# ATSAMRH707F18A device description
Architecture: CORTEX-M7; Family: SAMRH; Series: SAMRH707
Registers are 32-bit, read-write, no defined reset value unless marked. A register's access mark holds for its fields unless they carry their own. Offsets are from the block's base; [hi:lo] are bit positions.

## CHIPID — Chip Identifier
Instances: CHIPID 0x40100000
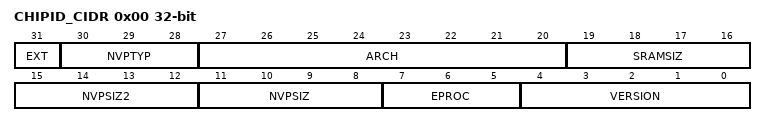
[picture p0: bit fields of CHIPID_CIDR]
0x00 CHIPID_CIDR ro — Chip ID Register
  [31] EXT — Extension Flag
  [30:28] NVPTYP — Nonvolatile Program Memory Type
    0=ROM; 1=ROMLESS (ROMless or on-chip Flash); 2=FLASH (Embedded Flash Memory); 3=ROM_FLASH (ROM and Embedded Flash Memory - NVPSIZ is ROM size - NVPSIZ2 is Flash size); 4=SRAM (SRAM emulating ROM)
  [27:20] ARCH — Architecture Identifier
    23=SAMRH707
  [19:16] SRAMSIZ — Internal SRAM Size
    0=_48K (48 Kbytes); 1=_192K (192 Kbytes); 2=_384K (384 Kbytes); 3=_6K (6 Kbytes); 4=_24K (24 Kbytes); 5=_4K (4 Kbytes); 6=_80K (80 Kbytes); 7=_160K (160 Kbytes); 8=_8K (8 Kbytes); 9=_16K (16 Kbytes); 10=_32K (32 Kbytes); 11=_64K (64 Kbytes); 12=_128K (128 Kbytes); 13=_256K (256 Kbytes); 14=_96K (96 Kbytes); 15=_512K (512 Kbytes)
  [15:12] NVPSIZ2 — Second Nonvolatile Program Memory Size
    0=NONE; 1=_8K (8 Kbytes); 2=_16K (16 Kbytes); 3=_32K (32 Kbytes); 5=_64K (64 Kbytes); 7=_128K (128 Kbytes); 9=_256K (256 Kbytes); 10=_512K (512 Kbytes); 12=_1024K (1024 Kbytes); 14=_2048K (2048 Kbytes)
  [11:8] NVPSIZ — Nonvolatile Program Memory Size
    0=NONE; 1=_8K (8 Kbytes); 2=_16K (16 Kbytes); 3=_32K (32 Kbytes); 5=_64K (64 Kbytes); 7=_128K (128 Kbytes); 8=_160K (160 Kbytes); 9=_256K (256 Kbytes); 10=_512K (512 Kbytes); 12=_1024K (1024 Kbytes); 14=_2048K (2048 Kbytes)
  [7:5] EPROC — Embedded Processor
    0=SAMx7 (Cortex-M7); 1=ARM946ES; 2=ARM7TDMI; 3=CM3 (Cortex-M3); 4=ARM920T; 5=ARM926EJS; 6=CA5 (Cortex-A5); 7=CM4 (Cortex-M4)
  [4:0] VERSION — Version of the Device
0x04 CHIPID_EXID ro — Chip ID Extension Register
  [31:0] EXID — Chip ID Extension
    0=PACKAGE_TYPE_164 (164-lead package); 1=PACKAGE_TYPE_BGA_484 (484-balls BGA package); 2=PACKAGE_TYPE_144 (144-lead package)

## CRCCU — Cyclic Redundancy Check Calculation Unit
Instances: CRCCU 0x40018000
0x00 CRCCU_DSCR — CRCCU Descriptor Base Register
  [31:9] DSCR — Descriptor Base Address
0x08 CRCCU_DMA_EN wo — CRCCU DMA Enable Register
  [0] DMAEN — DMA Enable
0x0C CRCCU_DMA_DIS wo — CRCCU DMA Disable Register
  [0] DMADIS — DMA Disable
0x10 CRCCU_DMA_SR ro — CRCCU DMA Status Register
  [0] DMASR — DMA Status
0x14 CRCCU_DMA_IER wo (atomic set of CRCCU_DMA_IMR) — CRCCU DMA Interrupt Enable Register
  [0] DMAIER — Interrupt Enable
0x18 CRCCU_DMA_IDR wo (atomic clear of CRCCU_DMA_IMR) — CRCCU DMA Interrupt Disable Register
  [0] DMAIDR — Interrupt Disable
0x1C CRCCU_DMA_IMR ro (atomic read) — CRCCU DMA Interrupt Mask Register
  [0] DMAIMR — Interrupt Mask
0x20 CRCCU_DMA_ISR ro (atomic read) — CRCCU DMA Interrupt Status Register
  [0] DMAISR — Interrupt Status
0x34 CRCCU_CR wo — CRCCU Control Register
  [0] RESET — CRC Computation Reset
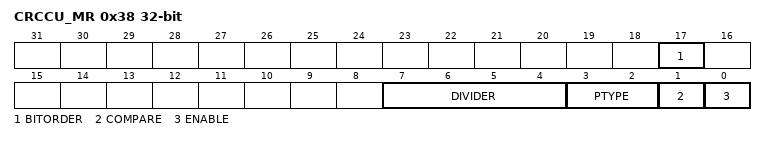
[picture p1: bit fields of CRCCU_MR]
0x38 CRCCU_MR — CRCCU Mode Register
  [17] BITORDER — Precomputation Bit Swap Operation of the CRC
    0=MSBFIRST (CRC computation is performed from the most significant bit to the least significant bit); 1=LSBFIRST (CRC computation is performed from the least significant bit to the most significant bit)
  [7:4] DIVIDER — Request Divider
  [3:2] PTYPE — Primitive Polynomial
    0=CCITT8023 (Polynom 0x04C11DB7); 1=CASTAGNOLI (Polynom 0x1EDC6F41); 2=CCITT16 (Polynom 0x1021)
  [1] COMPARE — CRC Compare
  [0] ENABLE — CRC Enable
0x3C CRCCU_SR ro — CRCCU Status Register
  [31:0] CRC — Cyclic Redundancy Check Value
0x40 CRCCU_IER wo (atomic set of CRCCU_IMR) — CRCCU Interrupt Enable Register
  [0] ERRIER — CRC Error Interrupt Enable
0x44 CRCCU_IDR wo (atomic clear of CRCCU_IMR) — CRCCU Interrupt Disable Register
  [0] ERRIDR — CRC Error Interrupt Disable
0x48 CRCCU_IMR ro (atomic read) — CRCCU Interrupt Mask Register
  [0] ERRIMR — CRC Error Interrupt Mask
0x4C CRCCU_ISR ro (atomic read) — CRCCU Interrupt Status Register
  [0] ERRISR — CRC Error Interrupt Status

## Notices in the file
Copyright (c) 2018 Microchip Technology Inc.
SPDX-License-Identifier: Apache-2.0
Licensed under the Apache License, Version 2.0 (the "License");
you may not use this file except in compliance with the License.
You may obtain a copy of the License at
http://www.apache.org/licenses/LICENSE-2.0
Unless required by applicable law or agreed to in writing, software
distributed under the License is distributed on an "AS IS" BASIS,
WITHOUT WARRANTIES OR CONDITIONS OF ANY KIND, either express or implied.
See the License for the specific language governing permissions and
limitations under the License.
